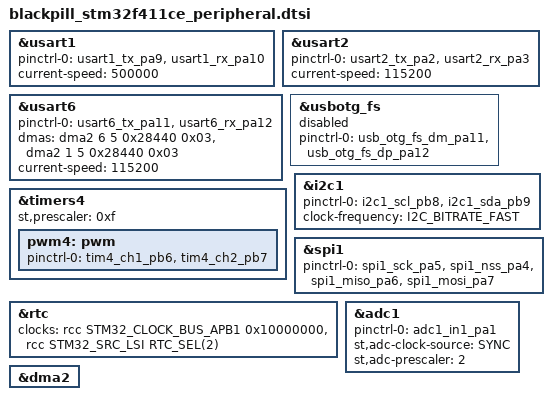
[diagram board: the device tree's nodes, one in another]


&usart1 {
	// Serving: Logging
	pinctrl-0 = <&usart1_tx_pa9 &usart1_rx_pa10>;
	pinctrl-names = "default";
	current-speed = <500000>;
	status = "okay";
};

&usart2 {
	pinctrl-0 = <&usart2_tx_pa2 &usart2_rx_pa3>;
	pinctrl-names = "default";
	current-speed = <115200>;
	status = "okay";
};

&usart6 {
	pinctrl-0 = <&usart6_tx_pa11 &usart6_rx_pa12>;
	dmas = <&dma2 6 5 0x28440 0x03>,
	       <&dma2 1 5 0x28440 0x03>;
	pinctrl-names = "default";
	current-speed = <115200>;
	status = "okay";
};

zephyr_udc0: &usbotg_fs {
	pinctrl-0 = <&usb_otg_fs_dm_pa11 &usb_otg_fs_dp_pa12>;
	pinctrl-names = "default";
	status = "disabled";
};

&timers4 {
	status = "okay";
	st,prescaler = <0xf>;

	pwm4: pwm {
		status = "okay";
		pinctrl-0 = <&tim4_ch1_pb6 &tim4_ch2_pb7>;
		pinctrl-names = "default";
	};
};

&i2c1 {
	pinctrl-0 = <&i2c1_scl_pb8 &i2c1_sda_pb9>;
	pinctrl-names = "default";
	status = "okay";
	clock-frequency = <I2C_BITRATE_FAST>;
};

&spi1 {
	pinctrl-0 = <&spi1_sck_pa5 &spi1_nss_pa4
		     &spi1_miso_pa6 &spi1_mosi_pa7>;
	pinctrl-names = "default";
	status = "okay";
};

&rtc {
	clocks = <&rcc STM32_CLOCK_BUS_APB1 0x10000000>,
		 <&rcc STM32_SRC_LSI RTC_SEL(2)>;
	status = "okay";
};

&adc1 {
	pinctrl-0 = <&adc1_in1_pa1>;
	pinctrl-names = "default";
	st,adc-clock-source = <SYNC>;
	st,adc-prescaler = <2>;
	status = "okay";
};

/*dmas start*/
&dma2 {
	status = "okay";
};
/*dmas end*/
